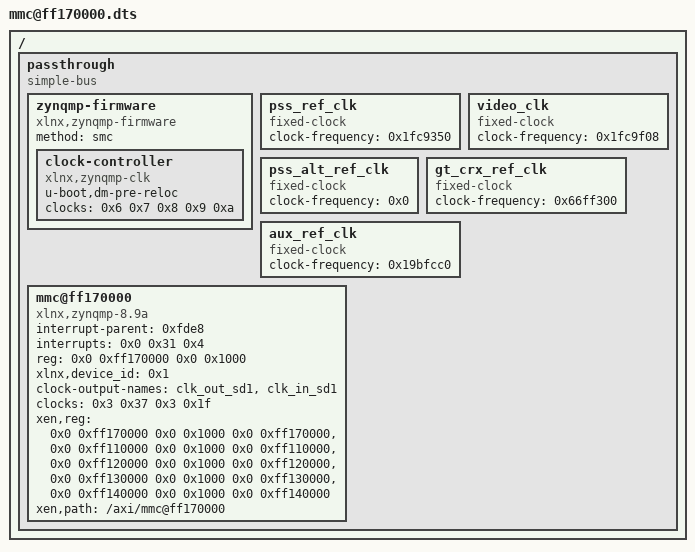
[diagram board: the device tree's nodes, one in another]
/dts-v1/;

/ {
	#address-cells = <0x2>;
	#size-cells = <0x2>;

	passthrough {
		compatible = "simple-bus";
		ranges;
		#address-cells = <0x2>;
		#size-cells = <0x2>;

		zynqmp-firmware {
			compatible = "xlnx,zynqmp-firmware", "xlnx,zynqmp";
			method = "smc";
			#power-domain-cells = <0x1>;
			phandle = <0x1>;

			clock-controller {
				u-boot,dm-pre-reloc;
				#clock-cells = <0x1>;
				compatible = "xlnx,zynqmp-clk";
				clocks = <0x6 0x7 0x8 0x9 0xa>;
				clock-names = "pss_ref_clk", "video_clk", "pss_alt_ref_clk", "aux_ref_clk", "gt_crx_ref_clk";
				phandle = <0x3>;
			};

		};

		pss_ref_clk {
			compatible = "fixed-clock";
			#clock-cells = <0x0>;
			clock-frequency = <0x1fc9350>;
			phandle = <0x6>;
		};

		video_clk {
			compatible = "fixed-clock";
			#clock-cells = <0x0>;
			clock-frequency = <0x1fc9f08>;
			phandle = <0x7>;
		};

		pss_alt_ref_clk {
			compatible = "fixed-clock";
			#clock-cells = <0x0>;
			clock-frequency = <0x0>;
			phandle = <0x8>;
		};

		gt_crx_ref_clk {
			compatible = "fixed-clock";
			#clock-cells = <0x0>;
			clock-frequency = <0x66ff300>;
			phandle = <0xa>;
		};

		aux_ref_clk {
			compatible = "fixed-clock";
			#clock-cells = <0x0>;
			clock-frequency = <0x19bfcc0>;
			phandle = <0x9>;
		};

		mmc@ff170000 {
			compatible = "xlnx,zynqmp-8.9a", "arasan,sdhci-8.9a";
			status = "okay";
			interrupt-parent = <0xfde8>;
			interrupts = <0x0 0x31 0x4>;
			reg = <0x0 0xff170000 0x0 0x1000>;
			xlnx,device_id = <0x1>;
			clock-names = "clk_xin", "clk_ahb";
			#clock-cells = <0x1>;
			clock-output-names = "clk_out_sd1", "clk_in_sd1";
			clocks = <0x3 0x37 0x3 0x1f>;
			phandle = <0x37>;
			xen,reg = <0x0 0xff170000 0x0 0x1000 0x0 0xff170000>, <0x0 0xff110000 0x0 0x1000 0x0 0xff110000>, <0x0 0xff120000 0x0 0x1000 0x0 0xff120000>, <0x0 0xff130000 0x0 0x1000 0x0 0xff130000>, <0x0 0xff140000 0x0 0x1000 0x0 0xff140000>;
			xen,path = "/axi/mmc@ff170000";
		};
	};
};
